# TM4C123GH6PM register map
Vendor: Texas Instruments; Series: TM4C; File version: 11073
CPU: CM4 r1p2, little endian, MPU, FPU, 3 interrupt priority bits
Registers are 32-bit, read-write, reset 0x1 unless marked. A register's access mark holds for its fields unless they carry their own. Offsets are from the block's base; [hi:lo] are bit positions; {n}, {i} and the like mark numbered series.

## USB0 — Register map for USB0 peripheral
Base 0x40050000; register names take the prefix USB0
0x00 FADDR 8-bit (reset mask 0x0) — USB Device Functional Address
  [6:0] USB_FADDR — Function Address
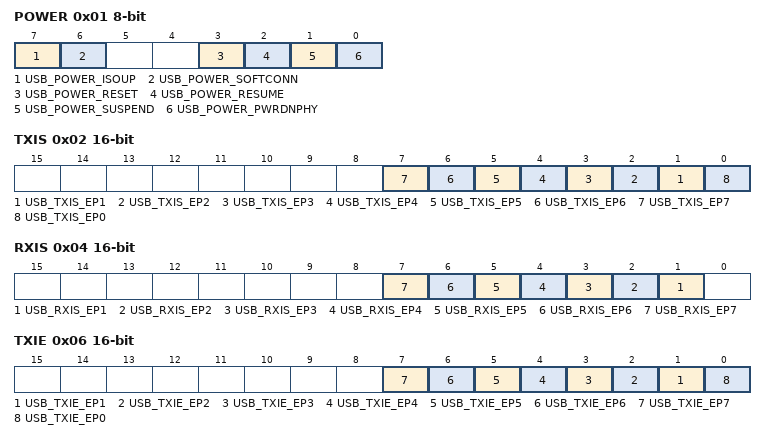
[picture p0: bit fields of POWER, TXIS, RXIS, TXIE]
0x01 POWER 8-bit (reset mask 0x0) — USB Power
  [7] USB_POWER_ISOUP — Isochronous Update
  [6] USB_POWER_SOFTCONN — Soft Connect/Disconnect
  [3] USB_POWER_RESET — RESET Signaling
  [2] USB_POWER_RESUME — RESUME Signaling
  [1] USB_POWER_SUSPEND — SUSPEND Mode
  [0] USB_POWER_PWRDNPHY — Power Down PHY
0x02 TXIS 16-bit (reset mask 0x0) — USB Transmit Interrupt Status
  [n] USB_TXIS_EP{n} (n=1..7) — TX Endpoint {n} Interrupt
  [0] USB_TXIS_EP0 — TX and RX Endpoint 0 Interrupt
0x04 RXIS 16-bit (reset mask 0x0) — USB Receive Interrupt Status
  [n] USB_RXIS_EP{n} (n=1..7) — RX Endpoint {n} Interrupt
0x06 TXIE 16-bit (reset mask 0x0) — USB Transmit Interrupt Enable
  [n] USB_TXIE_EP{n} (n=1..7) — TX Endpoint {n} Interrupt Enable
  [0] USB_TXIE_EP0 — TX and RX Endpoint 0 Interrupt Enable
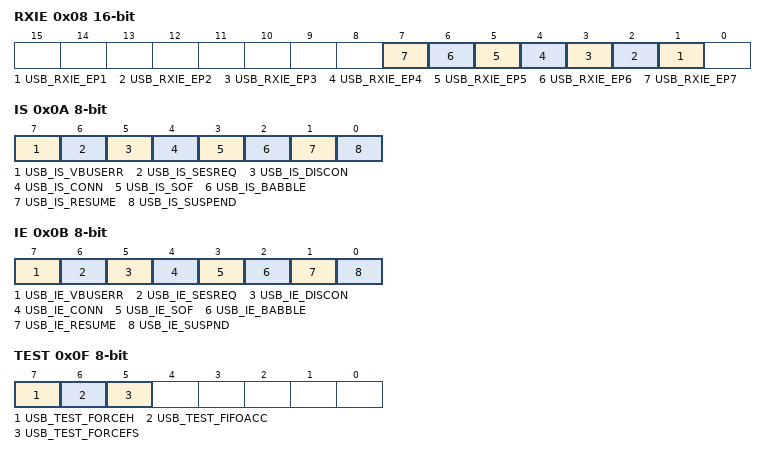
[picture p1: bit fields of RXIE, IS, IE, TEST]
0x08 RXIE 16-bit (reset mask 0x0) — USB Receive Interrupt Enable
  [n] USB_RXIE_EP{n} (n=1..7) — RX Endpoint {n} Interrupt Enable
0x0A IS 8-bit (reset mask 0x0) — USB General Interrupt Status
  [7] USB_IS_VBUSERR — VBUS Error
  [6] USB_IS_SESREQ — SESSION REQUEST
  [5] USB_IS_DISCON — Session Disconnect
  [4] USB_IS_CONN — Session Connect
  [3] USB_IS_SOF — Start of Frame
  [2] USB_IS_BABBLE — Babble Detected
  [1] USB_IS_RESUME — RESUME Signaling Detected
  [0] USB_IS_SUSPEND — SUSPEND Signaling Detected
0x0A IS 8-bit (reset mask 0x0) (USB0_ALT view) — USB General Interrupt Status
  [2] USB_IS_RESET — RESET Signaling Detected
0x0B IE 8-bit (reset mask 0x0) — USB Interrupt Enable
  [7] USB_IE_VBUSERR — Enable VBUS Error Interrupt
  [6] USB_IE_SESREQ — Enable Session Request
  [5] USB_IE_DISCON — Enable Disconnect Interrupt
  [4] USB_IE_CONN — Enable Connect Interrupt
  [3] USB_IE_SOF — Enable Start-of-Frame Interrupt
  [2] USB_IE_BABBLE — Enable Babble Interrupt
  [1] USB_IE_RESUME — Enable RESUME Interrupt
  [0] USB_IE_SUSPND — Enable SUSPEND Interrupt
0x0B IE 8-bit (reset mask 0x0) (USB0_ALT view) — USB Interrupt Enable
  [2] USB_IE_RESET — Enable RESET Interrupt
0x0C FRAME 16-bit (reset mask 0x0) — USB Frame Value
  [10:0] USB_FRAME — Frame Number
0x0E EPIDX 8-bit (reset mask 0x0) — USB Endpoint Index
  [3:0] USB_EPIDX_EPIDX — Endpoint Index
0x0F TEST 8-bit (reset mask 0x0) — USB Test Mode
  [7] USB_TEST_FORCEH — Force Host Mode
  [6] USB_TEST_FIFOACC — FIFO Access
  [5] USB_TEST_FORCEFS — Force Full-Speed Mode
{0x20+4i} FIFO{i} (reset mask 0x0) (i=0..7) — USB FIFO Endpoint {i}
  [31:0] USB_FIFO{i}_EPDATA — Endpoint Data
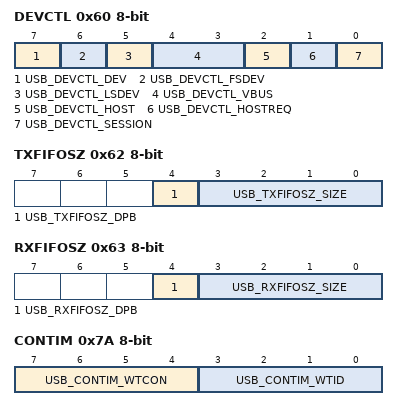
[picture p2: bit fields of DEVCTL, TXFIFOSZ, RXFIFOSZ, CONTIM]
0x60 DEVCTL 8-bit (reset mask 0x0) — USB Device Control
  [7] USB_DEVCTL_DEV — Device Mode
  [6] USB_DEVCTL_FSDEV — Full-Speed Device Detected
  [5] USB_DEVCTL_LSDEV — Low-Speed Device Detected
  [4:3] USB_DEVCTL_VBUS — VBUS Level
    0=USB_DEVCTL_VBUS_NONE (Below SessionEnd); 1=USB_DEVCTL_VBUS_SEND (Above SessionEnd, below AValid); 2=USB_DEVCTL_VBUS_AVALID (Above AValid, below VBUSValid); 3=USB_DEVCTL_VBUS_VALID (Above VBUSValid)
  [2] USB_DEVCTL_HOST — Host Mode
  [1] USB_DEVCTL_HOSTREQ — Host Request
  [0] USB_DEVCTL_SESSION — Session Start/End
0x62 TXFIFOSZ 8-bit (reset mask 0x0) — USB Transmit Dynamic FIFO Sizing
  [4] USB_TXFIFOSZ_DPB — Double Packet Buffer Support
  [3:0] USB_TXFIFOSZ_SIZE — Max Packet Size
    0=8; 1=16; 2=32; 3=64; 4=128; 5=256; 6=512; 7=1024; 8=2048
0x63 RXFIFOSZ 8-bit (reset mask 0x0) — USB Receive Dynamic FIFO Sizing
  [4] USB_RXFIFOSZ_DPB — Double Packet Buffer Support
  [3:0] USB_RXFIFOSZ_SIZE — Max Packet Size
    0=8; 1=16; 2=32; 3=64; 4=128; 5=256; 6=512; 7=1024; 8=2048
0x64 TXFIFOADD 16-bit (reset mask 0x0) — USB Transmit FIFO Start Address
  [8:0] USB_TXFIFOADD_ADDR — Transmit/Receive Start Address
0x66 RXFIFOADD 16-bit (reset mask 0x0) — USB Receive FIFO Start Address
  [8:0] USB_RXFIFOADD_ADDR — Transmit/Receive Start Address
0x7A CONTIM 8-bit (reset mask 0x0) — USB Connect Timing
  [7:4] USB_CONTIM_WTCON — Connect Wait
  [3:0] USB_CONTIM_WTID — Wait ID
0x7B VPLEN 8-bit (reset mask 0x0) — USB OTG VBUS Pulse Timing
  [7:0] USB_VPLEN_VPLEN — VBUS Pulse Length
0x7D FSEOF 8-bit (reset mask 0x0) — USB Full-Speed Last Transaction to End of Frame Timing
  [7:0] USB_FSEOF_FSEOFG — Full-Speed End-of-Frame Gap
0x7E LSEOF 8-bit (reset mask 0x0) — USB Low-Speed Last Transaction to End of Frame Timing
  [7:0] USB_LSEOF_LSEOFG — Low-Speed End-of-Frame Gap
{0x80+8i} TXFUNCADDR{i} 8-bit (reset mask 0x0) (i=0..7) — USB Transmit Functional Address Endpoint {i}
  [6:0] USB_TXFUNCADDR{i}_ADDR — Device Address
{0x82+8i} TXHUBADDR{i} 8-bit (reset mask 0x0) (i=0..7) — USB Transmit Hub Address Endpoint {i}
  [6:0] USB_TXHUBADDR{i}_ADDR — Hub Address
{0x83+8i} TXHUBPORT{i} 8-bit (reset mask 0x0) (i=0..7) — USB Transmit Hub Port Endpoint {i}
  [6:0] USB_TXHUBPORT{i}_PORT — Hub Port
{0x84+8i} RXFUNCADDR{i} 8-bit (reset mask 0x0) (i=1..7) — USB Receive Functional Address Endpoint {i}
  [6:0] USB_RXFUNCADDR{i}_ADDR — Device Address
{0x86+8i} RXHUBADDR{i} 8-bit (reset mask 0x0) (i=1..7) — USB Receive Hub Address Endpoint {i}
  [6:0] USB_RXHUBADDR{i}_ADDR — Hub Address
{0x87+8i} RXHUBPORT{i} 8-bit (reset mask 0x0) (i=1..7) — USB Receive Hub Port Endpoint {i}
  [6:0] USB_RXHUBPORT{i}_PORT — Hub Port
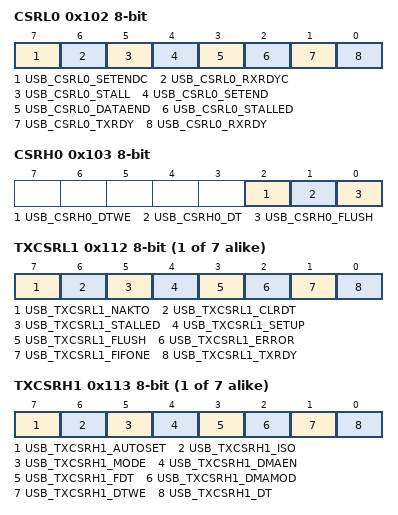
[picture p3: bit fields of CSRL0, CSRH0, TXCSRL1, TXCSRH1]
0x102 CSRL0 8-bit wo (reset mask 0x0) — USB Control and Status Endpoint 0 Low
  [7] USB_CSRL0_SETENDC — Setup End Clear
  [6] USB_CSRL0_RXRDYC — RXRDY Clear
  [5] USB_CSRL0_STALL — Send Stall
  [4] USB_CSRL0_SETEND — Setup End
  [3] USB_CSRL0_DATAEND — Data End
  [2] USB_CSRL0_STALLED — Endpoint Stalled
  [1] USB_CSRL0_TXRDY — Transmit Packet Ready
  [0] USB_CSRL0_RXRDY — Receive Packet Ready
0x102 CSRL0 8-bit wo (reset mask 0x0) (USB0_ALT view) — USB Control and Status Endpoint 0 Low
  [7] USB_CSRL0_NAKTO — NAK Timeout
  [6] USB_CSRL0_STATUS — STATUS Packet
  [5] USB_CSRL0_REQPKT — Request Packet
  [4] USB_CSRL0_ERROR — Error
  [3] USB_CSRL0_SETUP — Setup Packet
0x103 CSRH0 8-bit wo (reset mask 0x0) — USB Control and Status Endpoint 0 High
  [2] USB_CSRH0_DTWE — Data Toggle Write Enable
  [1] USB_CSRH0_DT — Data Toggle
  [0] USB_CSRH0_FLUSH — Flush FIFO
0x108 COUNT0 8-bit (reset mask 0x0) — USB Receive Byte Count Endpoint 0
  [6:0] USB_COUNT0_COUNT — FIFO Count
0x10A TYPE0 8-bit (reset mask 0x0) — USB Type Endpoint 0
  [7:6] USB_TYPE0_SPEED — Operating Speed
    2=USB_TYPE0_SPEED_FULL (Full); 3=USB_TYPE0_SPEED_LOW (Low)
0x10B NAKLMT 8-bit (reset mask 0x0) — USB NAK Limit
  [4:0] USB_NAKLMT_NAKLMT — EP0 NAK Limit
{0x100+0x10*i} TXMAXP{i} 16-bit (reset mask 0x0) (i=1..7) — USB Maximum Transmit Data Endpoint {i}
  [10:0] USB_TXMAXP{i}_MAXLOAD — Maximum Payload
{0x102+0x10*i} TXCSRL{i} 8-bit (reset mask 0x0) (i=1..7) — USB Transmit Control and Status Endpoint {i} Low
  [7] USB_TXCSRL{i}_NAKTO — NAK Timeout
  [6] USB_TXCSRL{i}_CLRDT — Clear Data Toggle
  [5] USB_TXCSRL{i}_STALLED — Endpoint Stalled
  [4] USB_TXCSRL{i}_SETUP — Setup Packet
  [3] USB_TXCSRL{i}_FLUSH — Flush FIFO
  [2] USB_TXCSRL{i}_ERROR — Error
  [1] USB_TXCSRL{i}_FIFONE — FIFO Not Empty
  [0] USB_TXCSRL{i}_TXRDY — Transmit Packet Ready
{0x102+0x10*i} TXCSRL{i} 8-bit (reset mask 0x0) (USB0_ALT view) (i=1..7) — USB Transmit Control and Status Endpoint {i} Low
  [4] USB_TXCSRL{i}_STALL — Send STALL
  [2] USB_TXCSRL{i}_UNDRN — Underrun
{0x103+0x10*i} TXCSRH{i} 8-bit (reset mask 0x0) (i=1..7) — USB Transmit Control and Status Endpoint {i} High
  [7] USB_TXCSRH{i}_AUTOSET — Auto Set
  [6] USB_TXCSRH{i}_ISO — Isochronous Transfers
  [5] USB_TXCSRH{i}_MODE — Mode
  [4] USB_TXCSRH{i}_DMAEN — DMA Request Enable
  [3] USB_TXCSRH{i}_FDT — Force Data Toggle
  [2] USB_TXCSRH{i}_DMAMOD — DMA Request Mode
  [1] USB_TXCSRH{i}_DTWE — Data Toggle Write Enable
  [0] USB_TXCSRH{i}_DT — Data Toggle
{0x104+0x10*i} RXMAXP{i} 16-bit (reset mask 0x0) (i=1..7) — USB Maximum Receive Data Endpoint {i}
  [10:0] USB_RXMAXP{i}_MAXLOAD — Maximum Payload
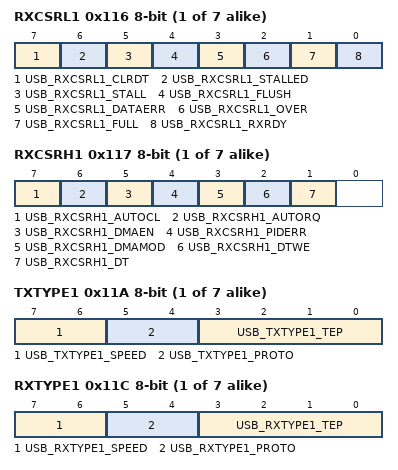
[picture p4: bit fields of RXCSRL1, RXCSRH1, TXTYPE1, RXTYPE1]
{0x106+0x10*i} RXCSRL{i} 8-bit (reset mask 0x0) (i=1..7) — USB Receive Control and Status Endpoint {i} Low
  [7] USB_RXCSRL{i}_CLRDT — Clear Data Toggle
  [6] USB_RXCSRL{i}_STALLED — Endpoint Stalled
  [5] USB_RXCSRL{i}_STALL — Send STALL
  [4] USB_RXCSRL{i}_FLUSH — Flush FIFO
  [3] USB_RXCSRL{i}_DATAERR — Data Error
  [2] USB_RXCSRL{i}_OVER — Overrun
  [1] USB_RXCSRL{i}_FULL — FIFO Full
  [0] USB_RXCSRL{i}_RXRDY — Receive Packet Ready
{0x106+0x10*i} RXCSRL{i} 8-bit (reset mask 0x0) (USB0_ALT view) (i=1..7) — USB Receive Control and Status Endpoint {i} Low
  [5] USB_RXCSRL{i}_REQPKT — Request Packet
  [3] USB_RXCSRL{i}_NAKTO — NAK Timeout
  [2] USB_RXCSRL{i}_ERROR — Error
{0x107+0x10*i} RXCSRH{i} 8-bit (reset mask 0x0) (i=1..7) — USB Receive Control and Status Endpoint {i} High
  [7] USB_RXCSRH{i}_AUTOCL — Auto Clear
  [6] USB_RXCSRH{i}_AUTORQ — Auto Request
  [5] USB_RXCSRH{i}_DMAEN — DMA Request Enable
  [4] USB_RXCSRH{i}_PIDERR — PID Error
  [3] USB_RXCSRH{i}_DMAMOD — DMA Request Mode
  [2] USB_RXCSRH{i}_DTWE — Data Toggle Write Enable
  [1] USB_RXCSRH{i}_DT — Data Toggle
{0x107+0x10*i} RXCSRH{i} 8-bit (reset mask 0x0) (USB0_ALT view) (i=1..7) — USB Receive Control and Status Endpoint {i} High
  [6] USB_RXCSRH{i}_ISO — Isochronous Transfers
  [4] USB_RXCSRH{i}_DISNYET — Disable NYET
{0x108+0x10*i} RXCOUNT{i} 16-bit (reset mask 0x0) (i=1..7) — USB Receive Byte Count Endpoint {i}
  [12:0] USB_RXCOUNT{i}_COUNT — Receive Packet Count
{0x10A+0x10*i} TXTYPE{i} 8-bit (reset mask 0x0) (i=1..7) — USB Host Transmit Configure Type Endpoint {i}
  [7:6] USB_TXTYPE{i}_SPEED — Operating Speed
    0=USB_TXTYPE{i}_SPEED_DFLT (Default); 2=USB_TXTYPE{i}_SPEED_FULL (Full); 3=USB_TXTYPE{i}_SPEED_LOW (Low)
  [5:4] USB_TXTYPE{i}_PROTO — Protocol
    0=USB_TXTYPE{i}_PROTO_CTRL (Control); 1=USB_TXTYPE{i}_PROTO_ISOC (Isochronous); 2=USB_TXTYPE{i}_PROTO_BULK (Bulk); 3=USB_TXTYPE{i}_PROTO_INT (Interrupt)
  [3:0] USB_TXTYPE{i}_TEP — Target Endpoint Number
{0x10B+0x10*i} TXINTERVAL{i} 8-bit (reset mask 0x0) (i=1..7) — USB Host Transmit Interval Endpoint {i}
  [7:0] USB_TXINTERVAL{i}_TXPOLL — TX Polling
{0x10B+0x10*i} TXINTERVAL{i} 8-bit (reset mask 0x0) (USB0_ALT view) (i=1..7) — USB Host Transmit Interval Endpoint {i}
  [7:0] USB_TXINTERVAL{i}_NAKLMT — NAK Limit
{0x10C+0x10*i} RXTYPE{i} 8-bit (reset mask 0x0) (i=1..7) — USB Host Configure Receive Type Endpoint {i}
  [7:6] USB_RXTYPE{i}_SPEED — Operating Speed
    0=USB_RXTYPE{i}_SPEED_DFLT (Default); 2=USB_RXTYPE{i}_SPEED_FULL (Full); 3=USB_RXTYPE{i}_SPEED_LOW (Low)
  [5:4] USB_RXTYPE{i}_PROTO — Protocol
    0=USB_RXTYPE{i}_PROTO_CTRL (Control); 1=USB_RXTYPE{i}_PROTO_ISOC (Isochronous); 2=USB_RXTYPE{i}_PROTO_BULK (Bulk); 3=USB_RXTYPE{i}_PROTO_INT (Interrupt)
  [3:0] USB_RXTYPE{i}_TEP — Target Endpoint Number
{0x10D+0x10*i} RXINTERVAL{i} 8-bit (reset mask 0x0) (i=1..7) — USB Host Receive Polling Interval Endpoint {i}
  [7:0] USB_RXINTERVAL{i}_TXPOLL — RX Polling
{0x10D+0x10*i} RXINTERVAL{i} 8-bit (reset mask 0x0) (USB0_ALT view) (i=1..7) — USB Host Receive Polling Interval Endpoint {i}
  [7:0] USB_RXINTERVAL{i}_NAKLMT — NAK Limit
{0x300+4i} RQPKTCOUNT{i} 16-bit (reset mask 0x0) (i=1..3) — USB Request Packet Count in Block Transfer Endpoint {i}
  [15:0] USB_RQPKTCOUNT{i} — Block Transfer Packet Count
{0x300+4i} RQPKTCOUNT{i} 16-bit (reset mask 0x0) (i=4..7) — USB Request Packet Count in Block Transfer Endpoint {i}
  [15:0] USB_RQPKTCOUNT{i}_COUNT — Block Transfer Packet Count
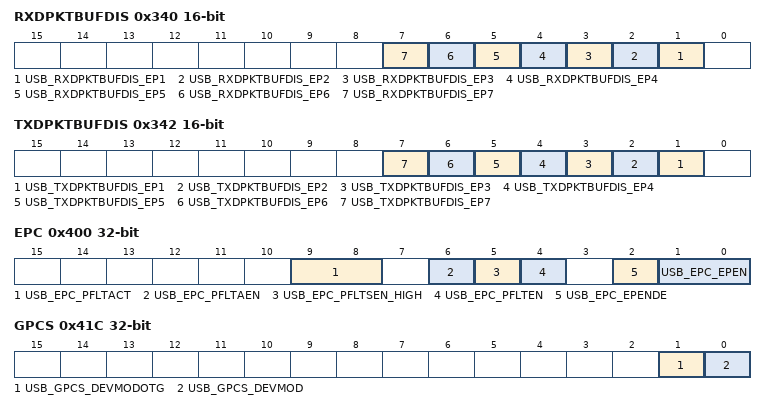
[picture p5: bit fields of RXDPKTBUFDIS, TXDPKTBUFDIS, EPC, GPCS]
0x340 RXDPKTBUFDIS 16-bit (reset mask 0x0) — USB Receive Double Packet Buffer Disable
  [n] USB_RXDPKTBUFDIS_EP{n} (n=1..7) — EP{n} RX Double-Packet Buffer Disable
0x342 TXDPKTBUFDIS 16-bit (reset mask 0x0) — USB Transmit Double Packet Buffer Disable
  [n] USB_TXDPKTBUFDIS_EP{n} (n=1..7) — EP{n} TX Double-Packet Buffer Disable
0x400 EPC (reset mask 0x0) — USB External Power Control
  [9:8] USB_EPC_PFLTACT — Power Fault Action
    0=USB_EPC_PFLTACT_UNCHG (Unchanged); 1=USB_EPC_PFLTACT_TRIS (Tristate); 2=USB_EPC_PFLTACT_LOW (Low); 3=USB_EPC_PFLTACT_HIGH (High)
  [6] USB_EPC_PFLTAEN — Power Fault Action Enable
  [5] USB_EPC_PFLTSEN_HIGH — Power Fault Sense
  [4] USB_EPC_PFLTEN — Power Fault Input Enable
  [2] USB_EPC_EPENDE — EPEN Drive Enable
  [1:0] USB_EPC_EPEN — External Power Supply Enable Configuration
    0=USB_EPC_EPEN_LOW (Power Enable Active Low); 1=USB_EPC_EPEN_HIGH (Power Enable Active High); 2=USB_EPC_EPEN_VBLOW (Power Enable High if VBUS Low); 3=USB_EPC_EPEN_VBHIGH (Power Enable High if VBUS High)
0x404 EPCRIS (reset mask 0x0) — USB External Power Control Raw Interrupt Status
  [0] USB_EPCRIS_PF — USB Power Fault Interrupt Status
0x408 EPCIM (reset mask 0x0) — USB External Power Control Interrupt Mask
  [0] USB_EPCIM_PF — USB Power Fault Interrupt Mask
0x40C EPCISC (reset mask 0x0) — USB External Power Control Interrupt Status and Clear
  [0] USB_EPCISC_PF — USB Power Fault Interrupt Status and Clear
0x410 DRRIS (reset mask 0x0) — USB Device RESUME Raw Interrupt Status
  [0] USB_DRRIS_RESUME — RESUME Interrupt Status
0x414 DRIM (reset mask 0x0) — USB Device RESUME Interrupt Mask
  [0] USB_DRIM_RESUME — RESUME Interrupt Mask
0x418 DRISC wo (reset mask 0x0) — USB Device RESUME Interrupt Status and Clear
  [0] USB_DRISC_RESUME — RESUME Interrupt Status and Clear
0x41C GPCS (reset mask 0x0) — USB General-Purpose Control and Status
  [1] USB_GPCS_DEVMODOTG — Enable Device Mode
  [0] USB_GPCS_DEVMOD — Device Mode
0x430 VDC (reset mask 0x0) — USB VBUS Droop Control
  [0] USB_VDC_VBDEN — VBUS Droop Enable
0x434 VDCRIS (reset mask 0x0) — USB VBUS Droop Control Raw Interrupt Status
  [0] USB_VDCRIS_VD — VBUS Droop Raw Interrupt Status
0x438 VDCIM (reset mask 0x0) — USB VBUS Droop Control Interrupt Mask
  [0] USB_VDCIM_VD — VBUS Droop Interrupt Mask
0x43C VDCISC (reset mask 0x0) — USB VBUS Droop Control Interrupt Status and Clear
  [0] USB_VDCISC_VD — VBUS Droop Interrupt Status and Clear
0x444 IDVRIS (reset mask 0x0) — USB ID Valid Detect Raw Interrupt Status
  [0] USB_IDVRIS_ID — ID Valid Detect Raw Interrupt Status
0x448 IDVIM (reset mask 0x0) — USB ID Valid Detect Interrupt Mask
  [0] USB_IDVIM_ID — ID Valid Detect Interrupt Mask
0x44C IDVISC (reset mask 0x0) — USB ID Valid Detect Interrupt Status and Clear
  [0] USB_IDVISC_ID — ID Valid Detect Interrupt Status and Clear
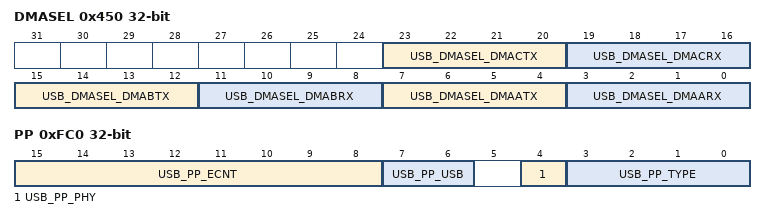
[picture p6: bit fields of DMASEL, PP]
0x450 DMASEL (reset mask 0x0) — USB DMA Select
  [23:20] USB_DMASEL_DMACTX — DMA C TX Select
  [19:16] USB_DMASEL_DMACRX — DMA C RX Select
  [15:12] USB_DMASEL_DMABTX — DMA B TX Select
  [11:8] USB_DMASEL_DMABRX — DMA B RX Select
  [7:4] USB_DMASEL_DMAATX — DMA A TX Select
  [3:0] USB_DMASEL_DMAARX — DMA A RX Select
0xFC0 PP (reset mask 0x0) — USB Peripheral Properties
  [15:8] USB_PP_ECNT — Endpoint Count
  [7:6] USB_PP_USB — USB Capability
    1=USB_PP_USB_DEVICE (DEVICE); 2=USB_PP_USB_HOSTDEVICE (HOST); 3=USB_PP_USB_OTG (OTG)
  [4] USB_PP_PHY — PHY Present
  [3:0] USB_PP_TYPE — Controller Type
    0=The first-generation USB controller
